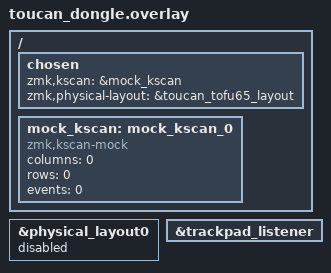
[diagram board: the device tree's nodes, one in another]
#include <input/processors.dtsi>
#include <dt-bindings/zmk/input_transform.h>
#include <dt-bindings/zmk/matrix_transform.h>
#include "toucan-layouts.dtsi"
#include "toucan.dtsi"
// Must come after toucan.dtsi: keys.h's 1-arg RC() must already be shadowed by matrix_transform.h (see toucan.dtsi).
#include "toucan-tofu65-layout.dtsi"

// The dongle keymap spans Toucan + Tofu65 (109 positions); keep toucan_tofu65_layout as the only layout so ZMK_KEYMAP_LEN and Studio use it.
&physical_layout0 {
    status = "disabled";
};

/ {
    chosen {
        zmk,kscan = &mock_kscan;
        zmk,physical-layout = &toucan_tofu65_layout;
    };

    mock_kscan: mock_kscan_0 {
        compatible = "zmk,kscan-mock";
        columns = <0>;
        rows = <0>;
        events = <0>;
    };
};

&trackpad_listener {
    status = "okay";
};
